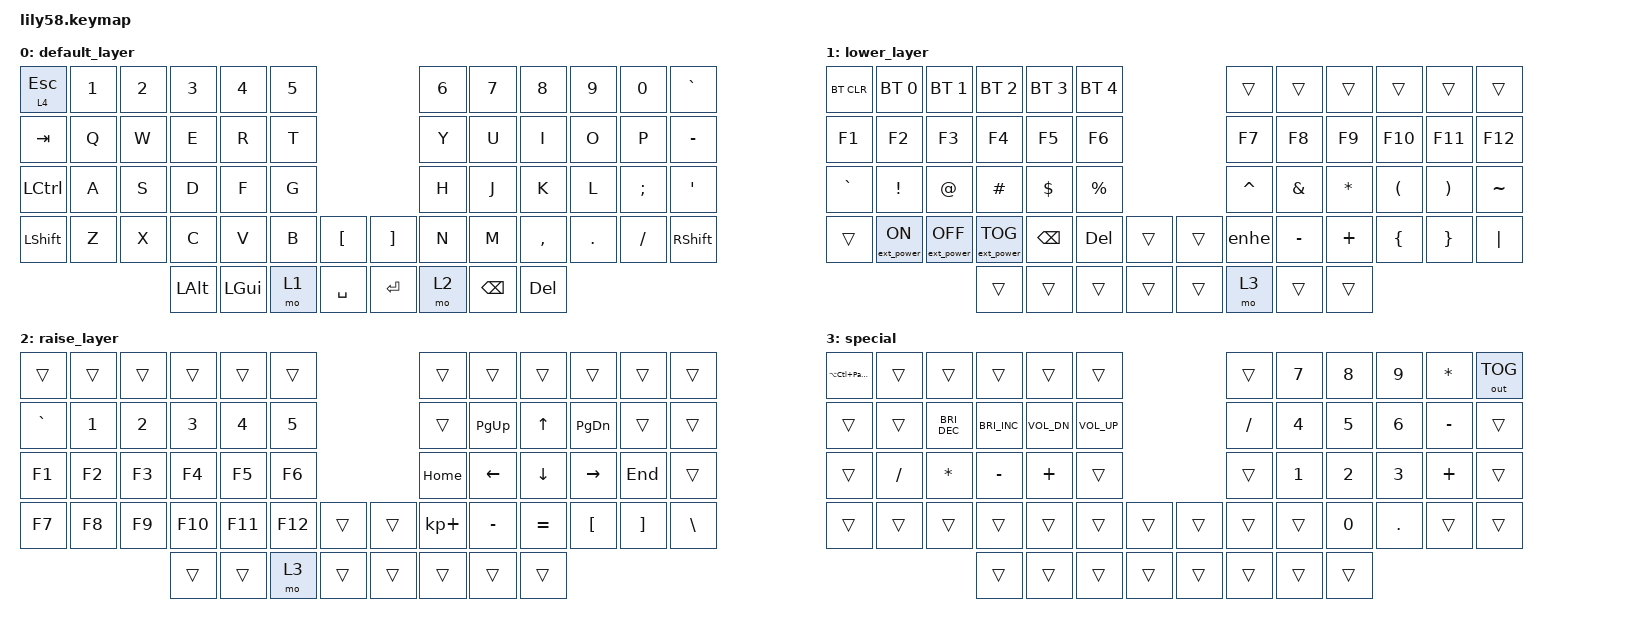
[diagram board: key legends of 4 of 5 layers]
/*
 * Copyright (c) 2020 The ZMK Contributors
 *
 * SPDX-License-Identifier: MIT
 */

#define ZMK_POINTING_DEFAULT_MOVE_VAL 1100  // default: 600
#define ZMK_POINTING_DEFAULT_SCRL_VAL 20    // default: 10

#include <behaviors.dtsi>
#include <behaviors/vfx.dtsi>
#include <dt-bindings/zmk/backlight.h>
#include <dt-bindings/zmk/bt.h>
#include <dt-bindings/zmk/ext_power.h>
#include <dt-bindings/zmk/outputs.h>
#include <dt-bindings/zmk/keys.h>
#include <dt-bindings/zmk/modifiers.h>
#include <dt-bindings/zmk/pointing.h>
#include <dt-bindings/zmk/rgb.h>
#include <dt-bindings/zmk/vfx.h>

/* Channel ids are positions in the overlay's channel list, glow first. */
#define VFX_CH_GLOW 0
#define VFX_CH_KEYS 1

/ {
    combos {
        compatible = "zmk,combos";

        combo_undo {
            bindings = <&kp LC(Z)>;
            key-positions = <37 38>;
        };

        combo_cut {
            bindings = <&kp LC(X)>;
            key-positions = <38 39>;
        };

        combo_copy {
            bindings = <&kp LC(C)>;
            key-positions = <39 40>;
        };

        combo_paste {
            bindings = <&kp LC(V)>;
            key-positions = <40 41>;
        };
    };

    /* One key per control rather than two, with right shift choosing which
     * part of the strip it lands on. Right rather than either shift: the
     * Mouse layer is held with the left pinky and every VFX key is left hand,
     * so a left shift chord would need three fingers on one hand.
     */
    behaviors {
        vfx_tog_ch: vfx_tog_ch {
            compatible = "zmk,behavior-mod-morph";
            #binding-cells = <0>;
            bindings = <&vfx VFX_TOG_ON(VFX_CH_KEYS)>, <&vfx VFX_TOG_ON(VFX_CH_GLOW)>;
            mods = <MOD_RSFT>;
        };

        vfx_next_ch: vfx_next_ch {
            compatible = "zmk,behavior-mod-morph";
            #binding-cells = <0>;
            bindings = <&vfx VFX_NEXT_ON(VFX_CH_KEYS)>, <&vfx VFX_NEXT_ON(VFX_CH_GLOW)>;
            mods = <MOD_RSFT>;
        };

        vfx_prev_ch: vfx_prev_ch {
            compatible = "zmk,behavior-mod-morph";
            #binding-cells = <0>;
            bindings = <&vfx VFX_PREV_ON(VFX_CH_KEYS)>, <&vfx VFX_PREV_ON(VFX_CH_GLOW)>;
            mods = <MOD_RSFT>;
        };

        vfx_bri_ch: vfx_bri_ch {
            compatible = "zmk,behavior-mod-morph";
            #binding-cells = <0>;
            bindings = <&vfx VFX_BRI_ON(VFX_CH_KEYS)>, <&vfx VFX_BRI_ON(VFX_CH_GLOW)>;
            mods = <MOD_RSFT>;
        };

        vfx_brd_ch: vfx_brd_ch {
            compatible = "zmk,behavior-mod-morph";
            #binding-cells = <0>;
            bindings = <&vfx VFX_BRD_ON(VFX_CH_KEYS)>, <&vfx VFX_BRD_ON(VFX_CH_GLOW)>;
            mods = <MOD_RSFT>;
        };

        vfx_hui_ch: vfx_hui_ch {
            compatible = "zmk,behavior-mod-morph";
            #binding-cells = <0>;
            bindings = <&vfx VFX_HUI_ON(VFX_CH_KEYS)>, <&vfx VFX_HUI_ON(VFX_CH_GLOW)>;
            mods = <MOD_RSFT>;
        };

        vfx_hud_ch: vfx_hud_ch {
            compatible = "zmk,behavior-mod-morph";
            #binding-cells = <0>;
            bindings = <&vfx VFX_HUD_ON(VFX_CH_KEYS)>, <&vfx VFX_HUD_ON(VFX_CH_GLOW)>;
            mods = <MOD_RSFT>;
        };

        vfx_spi_ch: vfx_spi_ch {
            compatible = "zmk,behavior-mod-morph";
            #binding-cells = <0>;
            bindings = <&vfx VFX_SPI_ON(VFX_CH_KEYS)>, <&vfx VFX_SPI_ON(VFX_CH_GLOW)>;
            mods = <MOD_RSFT>;
        };

        vfx_spd_ch: vfx_spd_ch {
            compatible = "zmk,behavior-mod-morph";
            #binding-cells = <0>;
            bindings = <&vfx VFX_SPD_ON(VFX_CH_KEYS)>, <&vfx VFX_SPD_ON(VFX_CH_GLOW)>;
            mods = <MOD_RSFT>;
        };
    };

    macros {
        enhe: enhe {
            compatible = "zmk,behavior-macro";
            #binding-cells = <0>;
            bindings = <&kt LEFT_ALT &kp KP_NUMBER_0 &kp KP_NUMBER_2 &kp KP_NUMBER_4 &kp KP_NUMBER_1 &kt LEFT_ALT>;
            label = "ENHE";
        };
    };

    keymap {
        compatible = "zmk,keymap";

        default_layer {
            // ------------------------------------------------------------------------------------------------------------
            // |  ESC  |  1  |  2  |  3   |  4   |  5   |                   |  6   |  7    |  8    |  9   |   0   |   `   |
            // |  TAB  |  Q  |  W  |  E   |  R   |  T   |                   |  Y   |  U    |  I    |  O   |   P   |   -   |
            // |  CTRL |  A  |  S  |  D   |  F   |  G   |                   |  H   |  J    |  K    |  L   |   ;   |   '   |
            // | SHIFT |  Z  |  X  |  C   |  V   |  B   |   "["  |  |  "]"  |  N   |  M    |  ,    |  .   |   /   | SHIFT |
            //                     | ALT  | GUI  | LOWER|  SPACE |  | ENTER | RAISE| BSPC  | DEL   |

            bindings = <
&lt 4 ESC  &kp N1  &kp N2  &kp N3    &kp N4    &kp N5                         &kp N6  &kp N7    &kp N8     &kp N9   &kp N0    &kp GRAVE
&kp TAB    &kp Q   &kp W   &kp E     &kp R     &kp T                          &kp Y   &kp U     &kp I      &kp O    &kp P     &kp MINUS
&kp LCTRL  &kp A   &kp S   &kp D     &kp F     &kp G                          &kp H   &kp J     &kp K      &kp L    &kp SEMI  &kp SQT
&kp LSHFT  &kp Z   &kp X   &kp C     &kp V     &kp B   &kp LBKT     &kp RBKT  &kp N   &kp M     &kp COMMA  &kp DOT  &kp FSLH  &kp RSHFT
                           &kp LALT  &kp LGUI  &mo 1   &kp SPACE    &kp RET   &mo 2   &kp BSPC  &kp DEL
            >;
        };

        lower_layer {
            // ------------------------------------------------------------------------------------------------------------
            // | BTCLR | BT1 | BT2 |  BT3 |  BT4 |  BT5 |                   |      |       |       |      |       |       |
            // |  F1   |  F2 |  F3 |  F4  |  F5  |  F6  |                   |  F7  |  F8   |  F9   |  F10 |  F11  |  F12  |
            // |   `   |  !  |  @  |  #   |  $   |  %   |                   |  ^   |  &    |  *    |  (   |   )   |   ~   |
            // |       |     |     |      |      |      |        |  |       |      |  _    |  +    |  {   |   }   |  "|"  |
            //                     |      |      |      |        |  |       |      |       |       |

            bindings = <
&bt BT_CLR  &bt BT_SEL 0      &bt BT_SEL 1       &bt BT_SEL 2       &bt BT_SEL 3   &bt BT_SEL 4                    &trans     &trans     &trans     &trans    &trans    &trans
&kp F1      &kp F2            &kp F3             &kp F4             &kp F5         &kp F6                          &kp F7     &kp F8     &kp F9     &kp F10   &kp F11   &kp F12
&kp GRAVE   &kp EXCL          &kp AT             &kp HASH           &kp DOLLAR     &kp PRCNT                       &kp CARET  &kp AMPS   &kp ASTRK  &kp LPAR  &kp RPAR  &kp TILDE
&trans      &ext_power EP_ON  &ext_power EP_OFF  &ext_power EP_TOG  &kp BACKSPACE  &kp DELETE    &trans    &trans  &enhe      &kp MINUS  &kp PLUS   &kp LBRC  &kp RBRC  &kp PIPE
                                                 &trans             &trans         &trans        &trans    &trans  &mo 3      &trans     &trans
            >;
        };

        raise_layer {
            // ------------------------------------------------------------------------------------------------------------
            // |       |     |     |      |      |      |                   |      |       |       |      |       |       |
            // |   `   |  1  |  2  |  3   |  4   |  5   |                   |  6   |   7   |   8   |  9   |   0   |       |
            // |   F1  |  F2 |  F3 |  F4  |  F5  |  F6  |                   |      |   <-  |   v   |  ^   |  ->   |       |
            // |   F7  |  F8 |  F9 |  F10 |  F11 |  F12 |        |  |       |  +   |   -   |   =   |  [   |   ]   |   \   |
            //                     |      |      |      |        |  |       |      |       |       |

            bindings = <
&trans     &trans  &trans  &trans   &trans   &trans                     &trans       &trans       &trans     &trans         &trans    &trans
&kp GRAVE  &kp N1  &kp N2  &kp N3   &kp N4   &kp N5                     &trans       &kp PAGE_UP  &kp UP     &kp PAGE_DOWN  &trans    &trans
&kp F1     &kp F2  &kp F3  &kp F4   &kp F5   &kp F6                     &kp HOME     &kp LEFT     &kp DOWN   &kp RIGHT      &kp END   &trans
&kp F7     &kp F8  &kp F9  &kp F10  &kp F11  &kp F12  &trans    &trans  &kp KP_PLUS  &kp MINUS    &kp EQUAL  &kp LBKT       &kp RBKT  &kp BSLH
                           &trans   &trans   &mo 3    &trans    &trans  &trans       &trans       &trans
            >;
        };

        special {
            bindings = <
&kp LA(LC(PAUSE_BREAK))  &trans    &trans         &trans         &trans        &trans                             &trans     &kp N7  &kp N8  &kp N9   &kp ASTERISK  &out OUT_TOG
&trans                   &trans    &kp C_BRI_DEC  &kp C_BRI_INC  &kp C_VOL_DN  &kp C_VOLUME_UP                    &kp SLASH  &kp N4  &kp N5  &kp N6   &kp MINUS     &trans
&trans                   &kp FSLH  &kp STAR       &kp MINUS      &kp PLUS      &trans                             &trans     &kp N1  &kp N2  &kp N3   &kp PLUS      &trans
&trans                   &trans    &trans         &trans         &trans        &trans           &trans    &trans  &trans     &trans  &kp N0  &kp DOT  &trans        &trans
                                                  &trans         &trans        &trans           &trans    &trans  &trans     &trans  &trans
            >;
        };

        Mouse {
            // Every VFX key drives the per-key channel on its own and the
            // underglow with right shift held. Position 0 is the &lt 4 that
            // reaches this layer, so it is held down throughout and can never
            // register a press of its own: nothing useful goes there.
            //
            // Key 1 sets the hue shift back to zero. The hue keys only step
            // up and down and the shift is stored, so without this there is
            // no way back to a scene's own colours once it has drifted.
            bindings = <
&trans  &vfx VFX_SET_HUE(0)  &trans        &trans        &trans        &trans                                &trans  &trans          &trans          &trans           &trans  &vfx_tog_ch
&trans  &bl BL_CYCLE         &vfx_spi_ch   &vfx_brd_ch   &vfx_bri_ch   &trans                                &trans  &msc SCRL_UP    &mmv MOVE_UP    &msc SCRL_DOWN   &trans  &trans
&trans  &bl BL_INC           &vfx_spd_ch   &vfx_hud_ch   &vfx_hui_ch   &trans                                &trans  &mmv MOVE_LEFT  &mmv MOVE_DOWN  &mmv MOVE_RIGHT  &trans  &trans
&trans  &bl BL_DEC           &bl BL_TOG    &vfx_prev_ch  &vfx_next_ch  &trans  &rgb_ug RGB_EFF    &trans     &trans  &trans          &trans          &trans           &trans  &trans
                                           &trans        &trans        &trans  &mkp LCLK          &mkp RCLK  &trans  &trans          &trans
            >;
        };
    };
};

#
